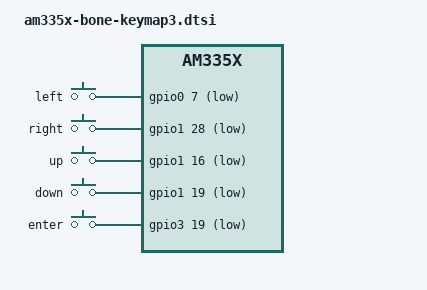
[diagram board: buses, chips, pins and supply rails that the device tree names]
/*
 * Copyright (C) 2012 Texas Instruments Incorporated - http://www.ti.com/
 *
 * This program is free software; you can redistribute it and/or modify
 * it under the terms of the GNU General Public License version 2 as
 * published by the Free Software Foundation.
 */

&ocp {
	P9_12_pinmux {
		status = "disabled";
	};
	P9_15_pinmux {
		/* gpio1[16] */
		status = "disabled";
	};
	P9_16_pinmux {
		/* gpio1[19] */
		status = "disabled";
	};
	P9_27_pinmux {
		/* gpio3[19] */
		status = "disabled";
	};
	P9_42_pinmux {
		status = "disabled";
	};
};

/ {
	gpio_keys {
		compatible = "gpio-keys";
		pinctrl-names = "default";
		pinctrl-0 = <&keymap3_pins>;

		#address-cells = <1>;
		#size-cells = <0>;

		button@1 {
			debounce_interval = <50>;
			linux,code = <105>;
			label = "left";
			gpios = <&gpio0 7 0x1>;
			gpio-key,wakeup;
			autorepeat;
		};
		button@2 {
			debounce_interval = <50>;
			linux,code = <106>;
			label = "right";
			gpios = <&gpio1 28 0x1>;
			gpio-key,wakeup;
			autorepeat;
		};
		button@3 {
			debounce_interval = <50>;
			linux,code = <103>;
			label = "up";
			gpios = <&gpio1 16 0x1>;
			gpio-key,wakeup;
			autorepeat;
		};
		button@4 {
			debounce_interval = <50>;
			linux,code = <108>;
			label = "down";
			gpios = <&gpio1 19 0x1>;
			gpio-key,wakeup;
			autorepeat;
		};
		button@5 {
			debounce_interval = <50>;
			linux,code = <28>;
			label = "enter";
			gpios = <&gpio3 19 0x1>;
			gpio-key,wakeup;
		};
	};
};
